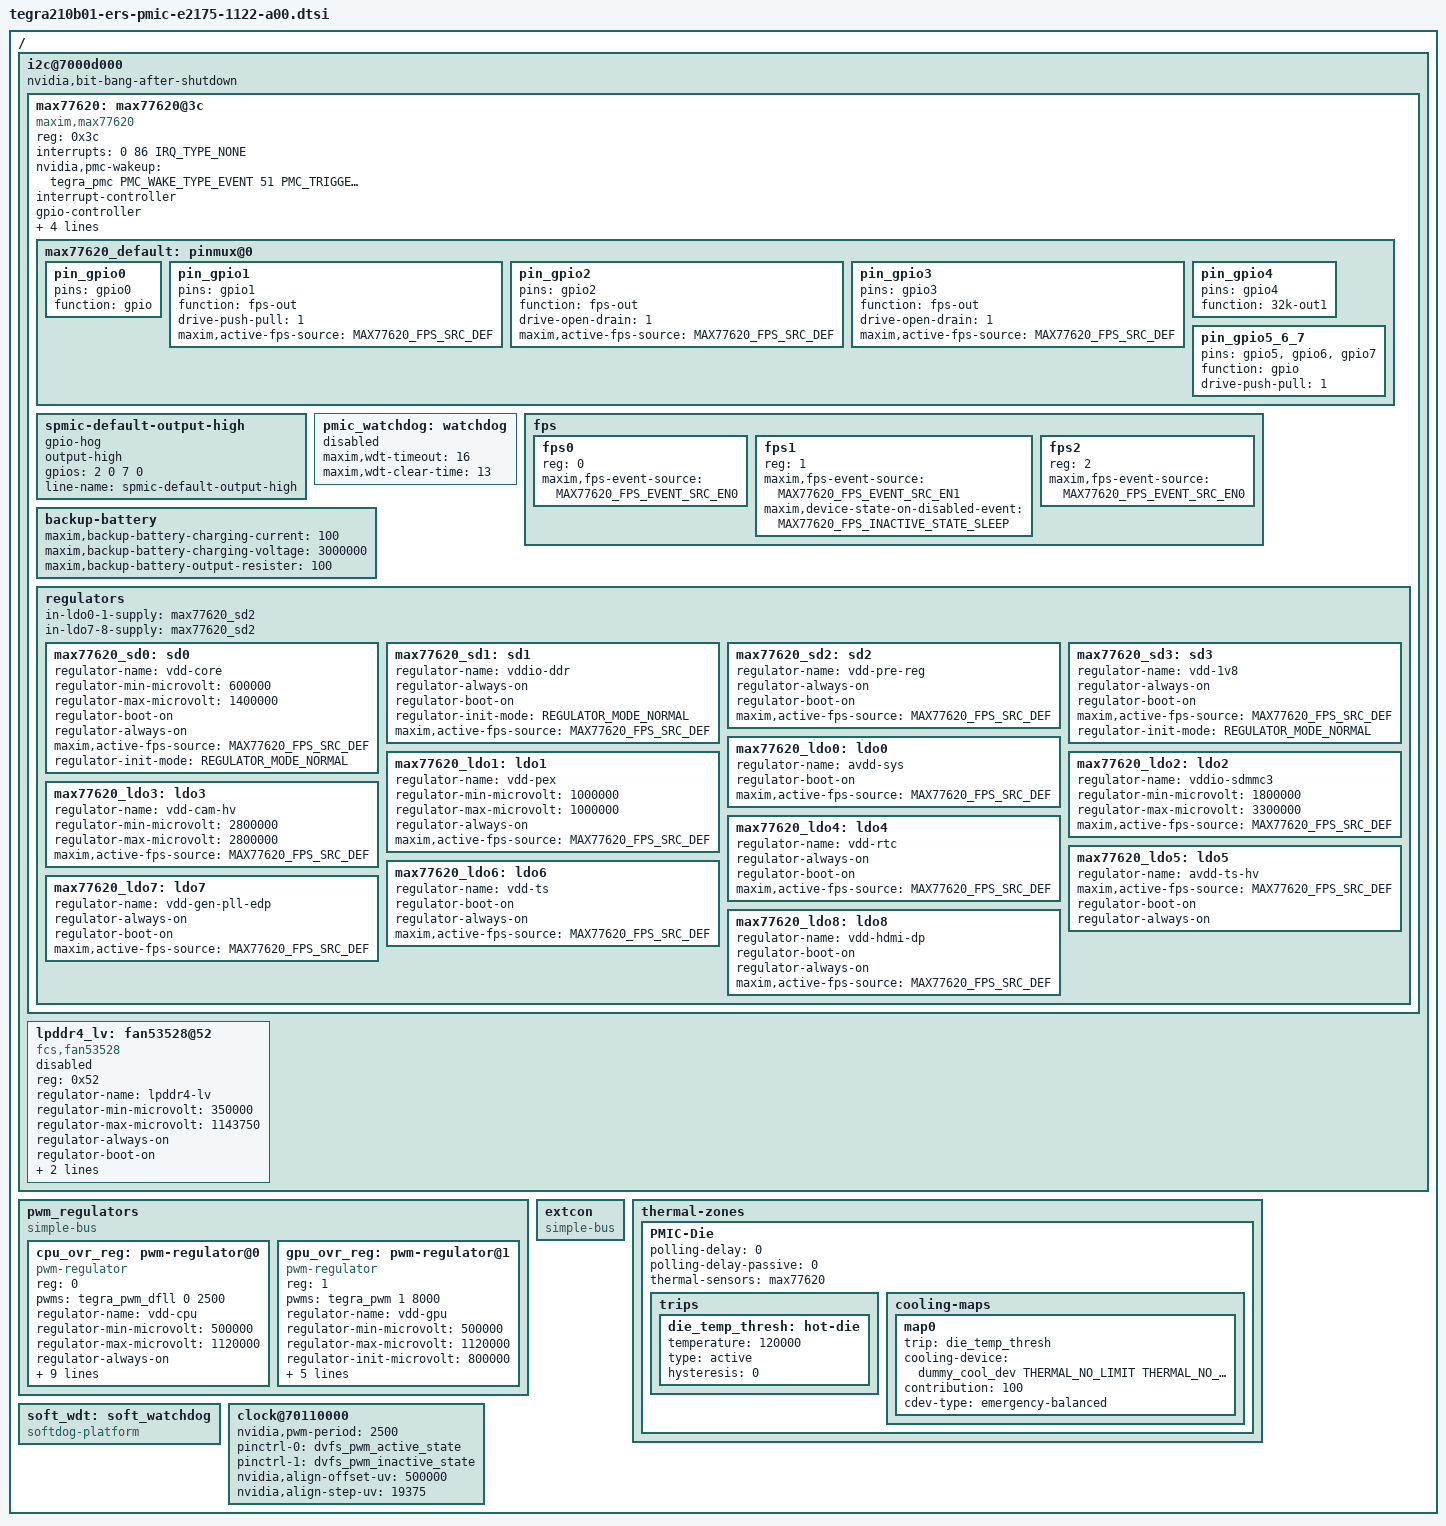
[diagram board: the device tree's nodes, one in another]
/*
 * Copyright (c) 2017, NVIDIA CORPORATION.  All rights reserved.
 *
 * This program is free software; you can redistribute it and/or modify
 * it under the terms of the GNU General Public License as published by
 * the Free Software Foundation; either version 2 of the License, or
 * (at your option) any later version.
 *
 * This program is distributed in the hope that it will be useful, but WITHOUT
 * ANY WARRANTY; without even the implied warranty of MERCHANTABILITY or
 * FITNESS FOR A PARTICULAR PURPOSE.  See the GNU General Public License for
 * more details.
 *
 * You should have received a copy of the GNU General Public License
 * along with this program.  If not, see <http://www.gnu.org/licenses/>.
 */

#include <dt-bindings/mfd/max77620.h>
#include <dt-bindings/regulator/regulator.h>
#include <dt-bindings/gpio/tegra-gpio.h>
#include <dt-bindings/thermal/thermal.h>
#include <dt-bindings/interrupt-controller/irq.h>
#include <dt-bindings/soc/tegra-pmc.h>

/ {
	i2c@7000d000 {
		nvidia,bit-bang-after-shutdown;

		max77620: max77620@3c {
			compatible = "maxim,max77620";
			reg = <0x3c>;
			interrupts = <0 86 IRQ_TYPE_NONE>;
			nvidia,pmc-wakeup = <&tegra_pmc
				PMC_WAKE_TYPE_EVENT 51 PMC_TRIGGER_TYPE_LOW>;

			#interrupt-cells = <2>;
                        interrupt-controller;

			gpio-controller;
			#gpio-cells = <2>;

			maxim,enable-clock32k-out;

			maxim,system-pmic-power-off;

			maxim,hot-die-threshold-temp = <110000>;
			#thermal-sensor-cells = <0>;

			pinctrl-names = "default";
			pinctrl-0 = <&max77620_default>;

			max77620_default: pinmux@0 {
				pin_gpio0 {
					pins = "gpio0";
					function = "gpio";
				};

				pin_gpio1 {
					pins = "gpio1";
					function = "fps-out";
					drive-push-pull = <1>;
					maxim,active-fps-source = <MAX77620_FPS_SRC_DEF>;
				};

				pin_gpio2 {
					pins = "gpio2";
					function = "fps-out";
					drive-open-drain = <1>;
					maxim,active-fps-source = <MAX77620_FPS_SRC_DEF>;
				};

				pin_gpio3 {
					pins = "gpio3";
					function = "fps-out";
					drive-open-drain = <1>;
					maxim,active-fps-source = <MAX77620_FPS_SRC_DEF>;
				};

				pin_gpio4 {
					pins = "gpio4";
					function = "32k-out1";
				};

				pin_gpio5_6_7 {
					pins = "gpio5", "gpio6", "gpio7";
					function = "gpio";
					drive-push-pull = <1>;
				};
			};

			spmic-default-output-high {
				gpio-hog;
				output-high;
				gpios = <2 0 7 0>;
				line-name = "spmic-default-output-high";
			};

			pmic_watchdog: watchdog {
				maxim,wdt-timeout = <16>;
				maxim,wdt-clear-time = <13>;
				status = "disabled";
			};

			fps {
				#address-cells = <1>;
				#size-cells = <0>;
				fps0 {
					reg = <0>;
					maxim,fps-event-source = <MAX77620_FPS_EVENT_SRC_EN0>;
				};

				fps1 {
					reg = <1>;
					maxim,fps-event-source = <MAX77620_FPS_EVENT_SRC_EN1>;
					maxim,device-state-on-disabled-event = <MAX77620_FPS_INACTIVE_STATE_SLEEP>;
				};

				fps2 {
					reg = <2>;
					maxim,fps-event-source = <MAX77620_FPS_EVENT_SRC_EN0>;
				};
			};

			backup-battery {
				maxim,backup-battery-charging-current = <100>;
				maxim,backup-battery-charging-voltage = <3000000>;
				maxim,backup-battery-output-resister = <100>;
			};

			regulators {
				in-ldo0-1-supply = <&max77620_sd2>;
				in-ldo7-8-supply = <&max77620_sd2>;

				max77620_sd0: sd0 {
					regulator-name = "vdd-core";
					regulator-min-microvolt = <600000>;
					regulator-max-microvolt = <1400000>;
					regulator-boot-on;
					regulator-always-on;
					maxim,active-fps-source = <MAX77620_FPS_SRC_DEF>;
					regulator-init-mode = <REGULATOR_MODE_NORMAL>;
				};

				max77620_sd1: sd1 {
					regulator-name = "vddio-ddr";
					regulator-always-on;
					regulator-boot-on;
					regulator-init-mode = <REGULATOR_MODE_NORMAL>;
					maxim,active-fps-source = <MAX77620_FPS_SRC_DEF>;
				};

				max77620_sd2: sd2 {
					regulator-name = "vdd-pre-reg";
					regulator-always-on;
					regulator-boot-on;
					maxim,active-fps-source = <MAX77620_FPS_SRC_DEF>;
				};

				max77620_sd3: sd3 {
					regulator-name = "vdd-1v8";
					regulator-always-on;
					regulator-boot-on;
					maxim,active-fps-source = <MAX77620_FPS_SRC_DEF>;
					regulator-init-mode = <REGULATOR_MODE_NORMAL>;
				};

				max77620_ldo0: ldo0 {
					regulator-name = "avdd-sys";
					regulator-boot-on;
					maxim,active-fps-source = <MAX77620_FPS_SRC_DEF>;
				};

				max77620_ldo1: ldo1 {
					regulator-name = "vdd-pex";
					regulator-min-microvolt = <1000000>;
					regulator-max-microvolt = <1000000>;
					regulator-always-on;
					maxim,active-fps-source = <MAX77620_FPS_SRC_DEF>;
				};

				max77620_ldo2: ldo2 {
					regulator-name = "vddio-sdmmc3";
					regulator-min-microvolt = <1800000>;
					regulator-max-microvolt = <3300000>;
					maxim,active-fps-source = <MAX77620_FPS_SRC_DEF>;
				};

				max77620_ldo3: ldo3 {
					regulator-name = "vdd-cam-hv";
					regulator-min-microvolt = <2800000>;
					regulator-max-microvolt = <2800000>;
					maxim,active-fps-source = <MAX77620_FPS_SRC_DEF>;
				};

				max77620_ldo4: ldo4 {
					regulator-name = "vdd-rtc";
					regulator-always-on;
					regulator-boot-on;
					maxim,active-fps-source = <MAX77620_FPS_SRC_DEF>;
				};

				max77620_ldo5: ldo5 {
					regulator-name = "avdd-ts-hv";
					maxim,active-fps-source = <MAX77620_FPS_SRC_DEF>;
					regulator-boot-on;
					regulator-always-on;
				};

				max77620_ldo6: ldo6 {
					regulator-name = "vdd-ts";
					regulator-boot-on;
					regulator-always-on;
					maxim,active-fps-source = <MAX77620_FPS_SRC_DEF>;
				};

				max77620_ldo7: ldo7 {
					regulator-name = "vdd-gen-pll-edp";
					regulator-always-on;
					regulator-boot-on;
					maxim,active-fps-source = <MAX77620_FPS_SRC_DEF>;
				};

				max77620_ldo8: ldo8 {
					regulator-name = "vdd-hdmi-dp";
					regulator-boot-on;
					regulator-always-on;
					maxim,active-fps-source = <MAX77620_FPS_SRC_DEF>;
				};
			};
		};

		lpddr4_lv: fan53528@52 {
			compatible = "fcs,fan53528";
			reg = <0x52>;
			status = "disabled";
			regulator-name = "lpddr4-lv";
			regulator-min-microvolt = <350000>;
			regulator-max-microvolt = <1143750>;
			regulator-always-on;
			regulator-boot-on;
			regulator-initial-mode = <REGULATOR_MODE_FAST>;
			fcs,suspend-voltage-selector = <1>;
		};
	};

	pwm_regulators {
		compatible = "simple-bus";
		#address-cells = <1>;
		#size-cells = <0>;

		cpu_ovr_reg: pwm-regulator@0 {
			status = "okay";
			reg = <0>;
			compatible = "pwm-regulator";
			pwms = <&tegra_pwm_dfll 0 2500>;
			regulator-name = "vdd-cpu";
			regulator-min-microvolt = <500000>;
			regulator-max-microvolt = <1120000>;
			regulator-always-on;
			voltage-table =
				<500000 0>, <519375 1>, <538750 2>,
				<558125 3>, <577500 4>, <596875 5>,
				<616250 6>, <635625 7>, <655000 8>,
				<674375 9>, <693750 10>, <713125 11>,
				<732500 12>, <751875 13>, <771250 14>,
				<790625 15>, <810000 16>, <829375 17>,
				<848750 18>, <868125 19>, <887500 20>,
				<906875 21>, <926250 22>, <945625 23>,
				<965000 24>, <984375 25>, <1003750 26>,
				<1023125 27>, <1042500 28>, <1061875 29>,
				<1081250 30>, <1100625 31>, <1120000 32>;
		};

		gpu_ovr_reg: pwm-regulator@1 {
			status = "okay";
			reg = <1>;
			compatible = "pwm-regulator";
			pwms = <&tegra_pwm 1 8000>;
			regulator-name = "vdd-gpu";
			regulator-min-microvolt = <500000>;
			regulator-max-microvolt = <1120000>;
			regulator-init-microvolt = <800000>;
			regulator-n-voltages = <124>;
			regulator-enable-ramp-delay = <2000>;
			enable-gpio = <&max77620 6 0>;
			regulator-settling-time-us;
			regulator-ramp-delay = <80>;
		};
	};

	extcon {
		compatible = "simple-bus";
		device_type = "external-connection";
		#address-cells = <1>;
		#size-cells = <0>;
	};

	thermal-zones {
		PMIC-Die {
			polling-delay = <0>; /* milliseconds */
			polling-delay-passive = <0>; /* milliseconds */

			thermal-sensors = <&max77620>;
			trips {
				die_temp_thresh: hot-die {
					temperature = <120000>;
					type = "active";
					hysteresis = <0>;
				};
			};

			cooling-maps {
				map0 {
					trip = <&die_temp_thresh>;
					cooling-device = <&dummy_cool_dev THERMAL_NO_LIMIT
						THERMAL_NO_LIMIT>;
					contribution = <100>;
					cdev-type = "emergency-balanced";
				};
			};
		};
	};

        soft_wdt: soft_watchdog {
                compatible = "softdog-platform";
                status = "okay";
        };

	clock@70110000 {
		nvidia,pwm-period = <2500>; /* 2.5us */
		pinctrl-names = "dvfs_pwm_enable", "dvfs_pwm_disable";
		pinctrl-0 = <&dvfs_pwm_active_state>;
		pinctrl-1 = <&dvfs_pwm_inactive_state>;
		nvidia,align-offset-uv = <500000>;
		nvidia,align-step-uv = <19375>;
	};
};
